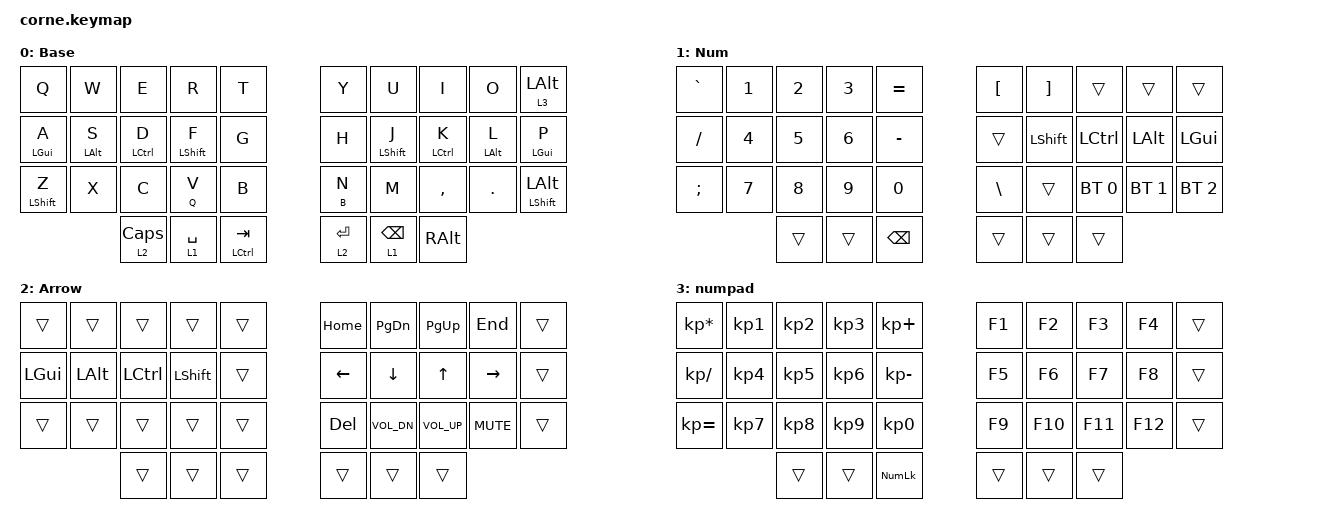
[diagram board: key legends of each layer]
/*
 * Copyright (c) 2020 The ZMK Contributors
 *
 * SPDX-License-Identifier: MIT
 */

#include <behaviors.dtsi>
#include <dt-bindings/zmk/keys.h>
#include <dt-bindings/zmk/bt.h>


#define AS(keycode) &as LS(keycode) keycode

/ {
    chosen {
        zmk,physical-layout = &foostan_corne_5col_layout;
    };

    combos{
        compatible = "zmk,combos";
        combo_esc { 
            timeout-ms = <50>;
            key-positions = <0 1>;
            layers = <0>;
            bindings = <&kp ESC>;
        };

        combo_dquote{
                timeout-ms = <50>;
                key-positions = <2 3>;
                layers = <0>;
                bindings = <&kp DQT>;  
            };

            combo_quote{
                timeout-ms = <50>;
                key-positions = <6 7>;
                layers = <0>;
                bindings = <&kp SQT>;
            };

            combo_lpar{
                timeout-ms = <50>;
                key-positions = <11 12>;
                layers = <0>;
                bindings = <&kp LPAR>;
            };

            combo_rpar{
                timeout-ms = <50>;
                key-positions = <17 18>;
                layers = <0>;
                bindings = <&kp RPAR>;
            };


            combo_lskshft{
                timeout-ms = <50>;
                key-positions = <12 13>;
                layers = <0>;
                bindings = <&sk LSHIFT>;
            };

            combo_rskshft{
                timeout-ms = <50>;
                key-positions = <16 17>;
                layers = <0>;
                bindings = <&sk RSHIFT>;
            };

    }; // combo ends

    behaviors {
        as: auto_shift {
            compatible = "zmk,behavior-hold-tap";
            #binding-cells = <2>;
            tapping_term_ms = <200>;
            quick_tap_ms = <0>;
            flavor = "tap-preferred";
            bindings = <&kp>, <&kp>;
        };


        hm: homerow_mods {
            compatible = "zmk,behavior-hold-tap";
            #binding-cells = <2>;
            tapping-term-ms = <150>;
            quick-tap-ms = <0>;
            flavor = "tap-preferred";
            bindings = <&kp>, <&kp>;
        };

 // // |  0  |  1  |  2  |  3  |  4  |                 |  5  |  6   |  7   |  8   | 9 |
// // |  10  |  11  |  12  |  13  |  14  |     |  15  |  16   |  17   |  18   | 19 | 
// // |  20  |  21  |  22  |  23  |  24  |     |  25  |  26   | 27    |  28   | 29 |
// //                            | 30 | 31 | 32 |    | 33 | 34  | 35 |

        hml: home_row_mod_left {
            compatible = "zmk,behavior-hold-tap";
            #binding-cells = <2>;
            flavor = "balanced";
            require-prior-idle-ms = <150>;
            tapping-term-ms = <150>;
            quick-tap-ms = <175>;
            bindings = <&kp>, <&kp>;
            hold-trigger-key-positions = < 0 1 2 3 4 10 11 12 13 14 20 21 22 23 24 30 31 32>; // List of keys on the right side of the keyboard
            hold-trigger-on-release;
        };
        hmr: home_row_mod_right {
            compatible = "zmk,behavior-hold-tap";
            #binding-cells = <2>;
            flavor = "balanced";
            require-prior-idle-ms = <150>;
            tapping-term-ms = <150>;
            quick-tap-ms = <175>;
            bindings = <&kp>, <&kp>;
            hold-trigger-key-positions = < 5 6 7 8 9 15 16 17 18 19 25 26 27 28 29 33 34 35 >; // List of keys on the left side of the keyboard
            hold-trigger-on-release;
        };

    };
        keymap {
                compatible = "zmk,keymap";

//                 default_layer {
// // -----------------------------------------------------------------------------------------
// // |  Q  |  W  |  E  |  R  |  T  |     |  Y  |  U   |  I   |  O   | P |
// // |  A  |  S  |  D  |  F  |  G  |     |  H  |  J   |  K   |  L   | ' | 
// // |  Z  |  X  |  C  |  V  |  B  |     |  N  |  M   | CTRL | META | . |
// //             | GUI | LWR | SPC |     | ENT | RSE  | BSPC |
//                         display-name = "Base";
//                         bindings = <
//    AS(Q) AS(W) AS(E) AS(R) AS(T)     AS(Y)   AS(U)  AS(I)     AS(O)     AS(P)
//    AS(A) AS(S) AS(D) AS(F) AS(G)     AS(H)   AS(J)  AS(K)     AS(L)     AS(SQT)
//    AS(Z) AS(X) AS(C) AS(V) AS(B)     AS(N)   AS(M)  &kp LCTL  &kp RALT  AS(DOT)
//         &kp LGUI &mo 1 &kp SPACE     AS(RET) &mo 2  &kp BSPC
//                         >;
//                 };

                default_layer {
                display-name = "Base";
                bindings = < 
                &kp Q            &kp W          &kp E             &kp R                 &kp T                     &kp Y        &kp U              &kp I               &kp O          &lt 3 LALT
                &hml LGUI A      &hml LALT S    &hml LCTRL D      &hml LSHFT F          &kp G                     &kp H        &hmr LSHFT J       &hmr LCTRL K        &hmr LALT L    &hmr LGUI P
                &hml LSHFT Z     &kp X          &kp C             &hm Q V               &kp B                     &hm B N      &kp M              &kp COMMA           &kp DOT        &hmr LSHFT LALT
                                                &lt 2 CAPS        &lt 1 SPACE           &hml LCTRL TAB            &lt 2 RET    &lt 1 BSPC         &kp RALT  
                >;
                };

//                 lower_layer {
// // -----------------------------------------------------------------------------------------
// // | !     |  @  |  #  |  $  |  %  |     |  ^  |  &  |  *  |  (  |  )  |
// // | BT1   | BT2 | BT3 | BT4 | BT5 |     | LFT | DWN |  UP | RGT |     |
// // | BTCLR |     |     |     |     |     |     |     |     |     |     |
// //               | GUI |     | SPC |     | ENT | ESC | TAB |
//                         display-name = "Lower";
//                         bindings = <
//    &kp EXCL     &kp AT       &kp HASH     &kp DLLR     &kp PRCNT        &kp CARET &kp AMPS  &kp KP_MULTIPLY &kp LPAR  &kp RPAR
//    &bt BT_SEL 0 &bt BT_SEL 1 &bt BT_SEL 2 &bt BT_SEL 3 &bt BT_SEL 4     &kp LEFT  &kp DOWN  &kp UP          &kp RIGHT &trans 
//    &bt BT_CLR   &trans       &trans       &trans       &trans           &trans    &trans    &trans          &trans    &trans 
//                              &kp LGUI     &trans       &kp SPACE        AS(RET)   &kp ESC   &kp TAB
//                         >;
//                 };
                num_layer {
                display-name = "Num";
                bindings = <
                &kp GRAVE        &kp N1          &kp N2          &kp N3          &kp EQUAL                       &kp LBKT        &kp RBKT         &trans           &trans                &trans 
                &kp FSLH         &kp N4          &kp N5          &kp N6          &kp MINUS                       &trans          &kp LSHFT        &kp LCTRL        &kp LALT              &kp LGUI 
                &kp SEMI         &kp N7          &kp N8          &kp N9          &kp N0                          &kp BSLH        &trans           &bt BT_SEL 0     &bt BT_SEL 1          &bt BT_SEL 2
                                                 &trans          &trans          &kp BSPC                        &trans          &trans           &trans
                >;
                };

//                 raise_layer {
// // -----------------------------------------------------------------------------------------
// // | 1! |  2@ |  3# |  4$ |  5% |     |  6^ |  7& |  8* |  9(  |  0)  |
// // | -_ |  =+ |  {  |  [  |  (  |     |  )  |  ]  |  }  |  /?  |  \|  |
// // | `~ |     |     |  ,< |  :  |     |  ;  |  .> | CTRL| META |      |
// //            | GUI | ESC | SPC |     | ENT |     | TAB |
//                         display-name = "Raise";
//                         bindings = <

//    AS(N1)    AS(N2)    AS(N3)    AS(N4)    AS(N5)        AS(N6)    AS(N7)    AS(N8)    AS(N9)   AS(N0)
//    AS(MINUS) AS(EQUAL) &kp LBRC  &kp LBKT  &kp LPAR      &kp RPAR  &kp RBKT  &kp RBRC  AS(FSLH) AS(BSLH)
//    AS(GRAVE) &trans    &trans    AS(COMMA) &kp COLON     &kp SEMI  AS(DOT)   &kp LCTRL &kp RALT &trans
//                        &kp LGUI  &kp ESC   &kp SPACE     AS(RET)   &trans    &kp TAB
//                         >;
//                 };

                arrow_layer {
                display-name = "Arrow";
                bindings = <
                &trans&trans&trans&trans&trans              &kp HOME&kp PG_DN&kp PG_UP&kp END&trans
                &kp LGUI&kp LALT&kp LCTRL&kp LSHFT&trans    &kp LEFT&kp DOWN&kp UP&kp RIGHT&trans
                &trans&trans&trans&trans&trans              &kp DEL&kp C_VOL_DN&kp C_VOL_UP&kp C_MUTE&trans
                &trans&trans&trans&trans&trans&trans
                >;
                };

                numpad_layer {
                display-name = "numpad";
                bindings = <
                 &kp KP_MULTIPLY&kp KP_N1&kp KP_N2&kp KP_N3&kp KP_PLUS      &kp F1&kp F2&kp F3&kp F4&trans
                &kp KP_DIVIDE&kp KP_N4&kp KP_N5&kp KP_N6&kp KP_MINUS        &kp F5&kp F6&kp F7&kp F8&trans
                &kp KP_EQUAL&kp KP_N7&kp KP_N8 &kp KP_N9&kp KP_N0           &kp F9&kp F10&kp F11&kp F12&trans
                &trans&trans&kp KP_NLCK&trans&trans&trans                       
                >;
                };

                extra_1 {
                        status = "reserved";
                // display-name = "numpad";
                // bindings = <
                //  &trans&trans&trans&trans&trans&trans&trans&trans&trans&trans
                // &trans&trans&trans&trans&trans&trans&trans&trans&trans&trans
                // &trans&trans&trans &trans&trans&trans&trans&trans&trans&trans
                // &trans&trans&trans&trans&trans&trans                       
                // >;
                };

                extra_2 {
                        status = "reserved";
                };
        };
};
